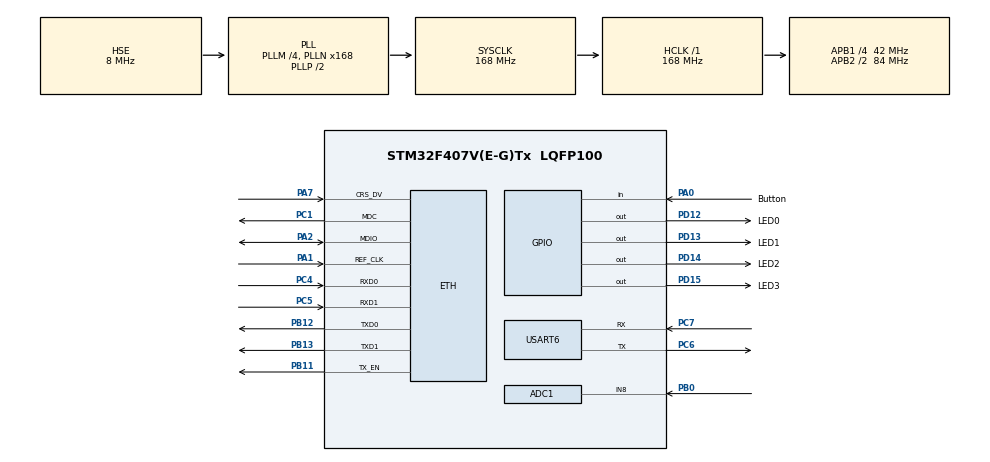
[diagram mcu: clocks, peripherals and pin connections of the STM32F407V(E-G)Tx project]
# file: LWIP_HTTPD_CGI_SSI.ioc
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ADC1.Channel-0\#ChannelRegularConversion=ADC_CHANNEL_8
ADC1.NbrOfConversionFlag=1
ADC1.Rank-0\#ChannelRegularConversion=1
ADC1.SamplingTime-0\#ChannelRegularConversion=ADC_SAMPLETIME_3CYCLES
ADC1.master=1
ETH.MediaInterface=ETH_MEDIA_INTERFACE_RMII
LWIP.DEFAULT_THREAD_STACKSIZE=2048
LWIP.GATEWAY_ADDRESS=192.168.031.001
LWIP.HTTPD_DEBUG=LWIP_DBG_ON
LWIP.HTTPD_DEBUG_TIMING=LWIP_DBG_ON
LWIP.IP_ADDRESS=192.168.031.090
LWIP.LWIP_DHCP=1
LWIP.LWIP_HTTPD=1
LWIP.LWIP_HTTPD_CGI=1
LWIP.LWIP_HTTPD_SSI=1
LWIP.MEM_SIZE=3000
LWIP.NETMASK_ADDRESS=255.255.255.000
LWIP.SLIPIF_THREAD_STACKSIZE=2048
LWIP.TCPIP_DEBUG=LWIP_DBG_ON
LWIP.TCPIP_THREAD_STACKSIZE=2048
LWIP.TCP_DEBUG=LWIP_DBG_ON
LWIP.TCP_INPUT_DEBUG=LWIP_DBG_ON
LWIP.TCP_MSS=720
LWIP.TCP_SND_BUF=1840
LWIP.TCP_WND=4096
LWIP.Version=v2.1.2_Cube
Mcu.Family=STM32F4
Mcu.Name=STM32F407V(E-G)Tx
Mcu.Package=LQFP100
NVIC.PriorityGroup=NVIC_PRIORITYGROUP_4
NVIC.TIM8_TRG_COM_TIM14_IRQn=true\:0\:0\:false\:false\:true\:false\:true
NVIC.TimeBase=TIM8_TRG_COM_TIM14_IRQn
NVIC.TimeBaseIP=TIM14
PA0-WKUP.GPIO_Label=Button
PA0-WKUP.Signal=GPIO_Input
PA1.Mode=RMII
PA1.Signal=ETH_REF_CLK
PA13.Mode=Serial_Wire
PA13.Signal=SYS_JTMS-SWDIO
PA14.Mode=Serial_Wire
PA14.Signal=SYS_JTCK-SWCLK
PA2.Mode=RMII
PA2.Signal=ETH_MDIO
PA7.Mode=RMII
PA7.Signal=ETH_CRS_DV
PB0.Signal=ADCx_IN8
PB11.Mode=RMII
PB11.Signal=ETH_TX_EN
PB12.Mode=RMII
PB12.Signal=ETH_TXD0
PB13.Mode=RMII
PB13.Signal=ETH_TXD1
PC1.Mode=RMII
PC1.Signal=ETH_MDC
PC4.Mode=RMII
PC4.Signal=ETH_RXD0
PC5.Mode=RMII
PC5.Signal=ETH_RXD1
PC6.Mode=Asynchronous
PC6.Signal=USART6_TX
PC7.Mode=Asynchronous
PC7.Signal=USART6_RX
PD12.GPIO_Label=LED0
PD12.Signal=GPIO_Output
PD13.GPIO_Label=LED1
PD13.Signal=GPIO_Output
PD14.GPIO_Label=LED2
PD14.Signal=GPIO_Output
PD15.GPIO_Label=LED3
PD15.Signal=GPIO_Output
PH0-OSC_IN.Mode=HSE-External-Oscillator
PH0-OSC_IN.Signal=RCC_OSC_IN
PH1-OSC_OUT.Mode=HSE-External-Oscillator
PH1-OSC_OUT.Signal=RCC_OSC_OUT
ProjectManager.HeapSize=0x2000
ProjectManager.StackSize=0x4000
ProjectManager.TargetToolchain=STM32CubeIDE
RCC.48MHZClocksFreq_Value=84000000
RCC.AHBFreq_Value=168000000
RCC.APB1CLKDivider=RCC_HCLK_DIV4
RCC.APB1Freq_Value=42000000
RCC.APB1TimFreq_Value=84000000
RCC.APB2CLKDivider=RCC_HCLK_DIV2
RCC.APB2Freq_Value=84000000
RCC.APB2TimFreq_Value=168000000
RCC.CortexFreq_Value=168000000
RCC.HCLKFreq_Value=168000000
RCC.HSE_VALUE=8000000
RCC.HSI_VALUE=16000000
RCC.LSE_VALUE=32768
RCC.PLLM=4
RCC.PLLN=168
RCC.PLLSourceVirtual=RCC_PLLSOURCE_HSE
RCC.SYSCLKFreq_VALUE=168000000
RCC.SYSCLKSource=RCC_SYSCLKSOURCE_PLLCLK
RCC.VCOOutputFreq_Value=336000000
SH.ADCx_IN8.0=ADC1_IN8,IN8
USART6.VirtualMode=VM_ASYNC
VP_LWIP_VS_Enabled.Mode=Enabled
VP_SYS_VS_tim14.Mode=TIM14
board=custom

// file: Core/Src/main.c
/* USER CODE BEGIN Header */
/**
  ******************************************************************************
  * @file           : main.c
  * @brief          : Main program body
  ******************************************************************************
  * @attention
  *
  * <h2><center>&copy; Copyright (c) 2020 STMicroelectronics.
  * All rights reserved.</center></h2>
  *
  * This software component is licensed by ST under BSD 3-Clause license,
  * the "License"; You may not use this file except in compliance with the
  * License. You may obtain a copy of the License at:
  *                        opensource.org/licenses/BSD-3-Clause
  *
  ******************************************************************************
  */
/* USER CODE END Header */

#include "main.h"
#include "adc.h"
#include "lwip.h"
#include "usart.h"
#include "gpio.h"

void SystemClock_Config(void);

int main(void)
{

  /* MCU Configuration--------------------------------------------------------*/

  /* Reset of all peripherals, Initializes the Flash interface and the Systick. */
  HAL_Init();

  /* Configure the system clock */
  SystemClock_Config();

  /* Initialize all configured peripherals */
  MX_GPIO_Init();
  MX_USART6_UART_Init();
  MX_LWIP_Init();
  MX_ADC1_Init();
  /* USER CODE BEGIN 2 */
  extern void User_App_Loop();
  User_App_Loop();
  /* USER CODE END 2 */

  /* Infinite loop */
  while (1)
  {

  }
}

void SystemClock_Config(void)
{
  RCC_OscInitTypeDef RCC_OscInitStruct = {0};
  RCC_ClkInitTypeDef RCC_ClkInitStruct = {0};

  /** Configure the main internal regulator output voltage
  */
  __HAL_RCC_PWR_CLK_ENABLE();
  __HAL_PWR_VOLTAGESCALING_CONFIG(PWR_REGULATOR_VOLTAGE_SCALE1);
  /** Initializes the CPU, AHB and APB busses clocks
  */
  RCC_OscInitStruct.OscillatorType = RCC_OSCILLATORTYPE_HSE;
  RCC_OscInitStruct.HSEState = RCC_HSE_ON;
  RCC_OscInitStruct.PLL.PLLState = RCC_PLL_ON;
  RCC_OscInitStruct.PLL.PLLSource = RCC_PLLSOURCE_HSE;
  RCC_OscInitStruct.PLL.PLLM = 4;
  RCC_OscInitStruct.PLL.PLLN = 168;
  RCC_OscInitStruct.PLL.PLLP = RCC_PLLP_DIV2;
  RCC_OscInitStruct.PLL.PLLQ = 4;
  if (HAL_RCC_OscConfig(&RCC_OscInitStruct) != HAL_OK)
  {
    Error_Handler();
  }
  /** Initializes the CPU, AHB and APB busses clocks
  */
  RCC_ClkInitStruct.ClockType = RCC_CLOCKTYPE_HCLK|RCC_CLOCKTYPE_SYSCLK
                              |RCC_CLOCKTYPE_PCLK1|RCC_CLOCKTYPE_PCLK2;
  RCC_ClkInitStruct.SYSCLKSource = RCC_SYSCLKSOURCE_PLLCLK;
  RCC_ClkInitStruct.AHBCLKDivider = RCC_SYSCLK_DIV1;
  RCC_ClkInitStruct.APB1CLKDivider = RCC_HCLK_DIV4;
  RCC_ClkInitStruct.APB2CLKDivider = RCC_HCLK_DIV2;

  if (HAL_RCC_ClockConfig(&RCC_ClkInitStruct, FLASH_LATENCY_5) != HAL_OK)
  {
    Error_Handler();
  }
}

 /**
  * @brief  Period elapsed callback in non blocking mode
  * @note   This function is called  when TIM14 interrupt took place, inside
  * HAL_TIM_IRQHandler(). It makes a direct call to HAL_IncTick() to increment
  * a global variable "uwTick" used as application time base.
  * @param  htim : TIM handle
  * @retval None
  */
void HAL_TIM_PeriodElapsedCallback(TIM_HandleTypeDef *htim)
{
  if (htim->Instance == TIM14) {
    HAL_IncTick();
  }
}

void Error_Handler(void)
{
}

/************************ (C) COPYRIGHT STMicroelectronics *****END OF FILE****/
